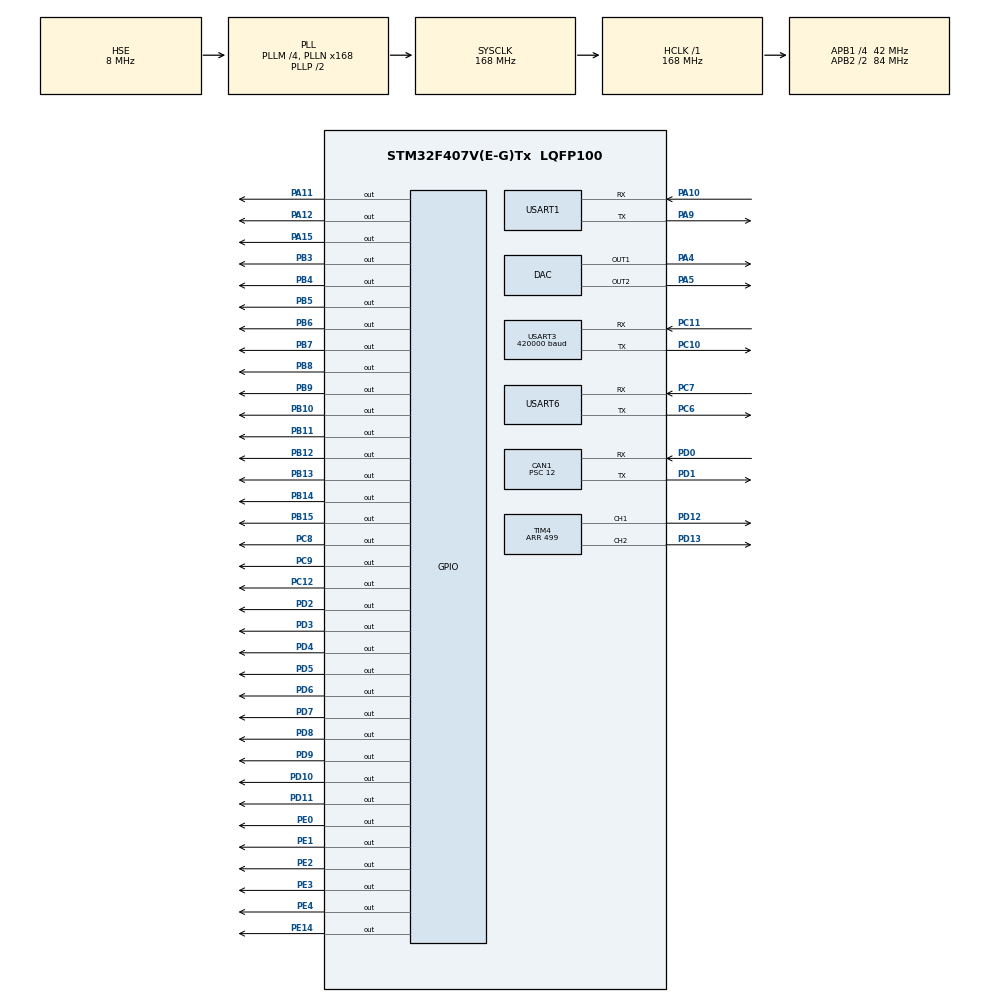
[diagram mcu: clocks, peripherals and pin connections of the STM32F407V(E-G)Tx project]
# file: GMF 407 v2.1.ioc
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CAN1.BS1=CAN_BS1_11TQ
CAN1.BS2=CAN_BS2_2TQ
CAN1.CalculateBaudRate=250000
CAN1.CalculateTimeBit=3999.99
CAN1.CalculateTimeQuantum=285.7142857142857
CAN1.Prescaler=12
Dma.Request0=USART3_RX
Dma.USART3_RX.0.Direction=DMA_PERIPH_TO_MEMORY
Dma.USART3_RX.0.FIFOMode=DMA_FIFOMODE_DISABLE
Dma.USART3_RX.0.Instance=DMA1_Stream1
Dma.USART3_RX.0.MemDataAlignment=DMA_MDATAALIGN_BYTE
Dma.USART3_RX.0.MemInc=DMA_MINC_ENABLE
Dma.USART3_RX.0.Mode=DMA_CIRCULAR
Dma.USART3_RX.0.PeriphDataAlignment=DMA_PDATAALIGN_BYTE
Dma.USART3_RX.0.PeriphInc=DMA_PINC_DISABLE
Dma.USART3_RX.0.Priority=DMA_PRIORITY_LOW
Mcu.Family=STM32F4
Mcu.Name=STM32F407V(E-G)Tx
Mcu.Package=LQFP100
NVIC.CAN1_RX0_IRQn=true\:0\:0\:false\:false\:true\:true\:true
NVIC.CAN1_RX1_IRQn=true\:0\:0\:false\:false\:true\:true\:true
NVIC.DMA1_Stream1_IRQn=true\:0\:0\:false\:false\:true\:false\:true
NVIC.PriorityGroup=NVIC_PRIORITYGROUP_4
NVIC.USART3_IRQn=true\:0\:0\:false\:false\:true\:true\:true
PA10.Mode=Asynchronous
PA10.Signal=USART1_RX
PA11.Signal=GPIO_Output
PA12.Signal=GPIO_Output
PA15.Signal=GPIO_Output
PA4.Signal=COMP_DAC1_group
PA5.Signal=COMP_DAC2_group
PA9.Mode=Asynchronous
PA9.Signal=USART1_TX
PB10.Signal=GPIO_Output
PB11.Signal=GPIO_Output
PB12.Signal=GPIO_Output
PB13.Signal=GPIO_Output
PB14.Signal=GPIO_Output
PB15.Signal=GPIO_Output
PB3.Signal=GPIO_Output
PB4.Signal=GPIO_Output
PB5.Signal=GPIO_Output
PB6.Signal=GPIO_Output
PB7.Signal=GPIO_Output
PB8.Signal=GPIO_Output
PB9.Signal=GPIO_Output
PC10.Mode=Asynchronous
PC10.Signal=USART3_TX
PC11.Mode=Asynchronous
PC11.Signal=USART3_RX
PC12.Signal=GPIO_Output
PC6.Mode=Asynchronous
PC6.Signal=USART6_TX
PC7.Mode=Asynchronous
PC7.Signal=USART6_RX
PC8.Signal=GPIO_Output
PC9.Signal=GPIO_Output
PD0.Mode=CAN_Activate
PD0.Signal=CAN1_RX
PD1.Mode=CAN_Activate
PD1.Signal=CAN1_TX
PD10.Signal=GPIO_Output
PD11.Signal=GPIO_Output
PD12.Signal=S_TIM4_CH1
PD13.Signal=S_TIM4_CH2
PD2.Signal=GPIO_Output
PD3.Signal=GPIO_Output
PD4.Signal=GPIO_Output
PD5.Signal=GPIO_Output
PD6.Signal=GPIO_Output
PD7.Signal=GPIO_Output
PD8.Signal=GPIO_Output
PD9.Signal=GPIO_Output
PE0.Signal=GPIO_Output
PE1.Signal=GPIO_Output
PE14.Signal=GPIO_Output
PE2.Signal=GPIO_Output
PE3.Signal=GPIO_Output
PE4.Signal=GPIO_Output
PH0-OSC_IN.Mode=HSE-External-Oscillator
PH0-OSC_IN.Signal=RCC_OSC_IN
PH1-OSC_OUT.Mode=HSE-External-Oscillator
PH1-OSC_OUT.Signal=RCC_OSC_OUT
ProjectManager.HeapSize=0x200
ProjectManager.StackSize=0x400
ProjectManager.TargetToolchain=STM32CubeIDE
RCC.48MHZClocksFreq_Value=84000000
RCC.AHBFreq_Value=168000000
RCC.APB1CLKDivider=RCC_HCLK_DIV4
RCC.APB1Freq_Value=42000000
RCC.APB1TimFreq_Value=84000000
RCC.APB2CLKDivider=RCC_HCLK_DIV2
RCC.APB2Freq_Value=84000000
RCC.APB2TimFreq_Value=168000000
RCC.CortexFreq_Value=168000000
RCC.HCLKFreq_Value=168000000
RCC.HSE_VALUE=8000000
RCC.HSI_VALUE=16000000
RCC.LSE_VALUE=32768
RCC.PLLM=4
RCC.PLLN=168
RCC.PLLSourceVirtual=RCC_PLLSOURCE_HSE
RCC.SYSCLKFreq_VALUE=168000000
RCC.SYSCLKSource=RCC_SYSCLKSOURCE_PLLCLK
RCC.VCOOutputFreq_Value=336000000
SH.COMP_DAC1_group.0=DAC_OUT1,DAC_OUT1
SH.COMP_DAC2_group.0=DAC_OUT2,DAC_OUT2
SH.S_TIM4_CH1.0=TIM4_CH1,PWM Generation1 CH1
SH.S_TIM4_CH2.0=TIM4_CH2,PWM Generation2 CH2
TIM4.Channel-PWM\ Generation1\ CH1=TIM_CHANNEL_1
TIM4.Channel-PWM\ Generation2\ CH2=TIM_CHANNEL_2
TIM4.Period=499
USART1.VirtualMode=VM_ASYNC
USART3.BaudRate=420000
USART3.VirtualMode=VM_ASYNC
USART6.VirtualMode=VM_ASYNC
VP_TIM4_VS_ClockSourceINT.Mode=Internal
board=custom

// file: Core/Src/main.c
/* USER CODE BEGIN Header */
/**
  ******************************************************************************
  * @file           : main.c
  * @brief          : Main program body
  ******************************************************************************
  * @attention
  *
  * <h2><center>&copy; Copyright (c) 2022 STMicroelectronics.
  * All rights reserved.</center></h2>
  *
  * This software component is licensed by ST under BSD 3-Clause license,
  * the "License"; You may not use this file except in compliance with the
  * License. You may obtain a copy of the License at:
  *                        opensource.org/licenses/BSD-3-Clause
  *
  ******************************************************************************
  */
/* USER CODE END Header */
#include "main.h"
#include "can.h"
#include "dac.h"
#include "dma.h"
#include "tim.h"
#include "usart.h"
#include "gpio.h"

/* USER CODE BEGIN Includes */
#include "radio.h"
#include "votol.h"
#include "can_stuff.h"
/* USER CODE END Includes */

void SystemClock_Config(void);

int main(void)
{

  /* MCU Configuration--------------------------------------------------------*/

  /* Reset of all peripherals, Initializes the Flash interface and the Systick. */
  HAL_Init();

  /* Configure the system clock */
  SystemClock_Config();

  /* Initialize all configured peripherals */
  MX_GPIO_Init();
  MX_TIM4_Init();
  MX_DMA_Init();
  MX_USART1_UART_Init();
  MX_USART3_UART_Init();
  MX_USART6_UART_Init();
  MX_DAC_Init();
  MX_CAN1_Init();
  /* USER CODE BEGIN 2 */
//  start_radio(&huart3);

  start_votol();

  HAL_UART_Receive_DMA(&huart3, &serial_byte, 1);
  /* USER CODE END 2 */

  /* Infinite loop */
  /* USER CODE BEGIN WHILE */
  while (1)
  {
	  kontrol_votol();
	  HAL_Delay(50);
    /* USER CODE END WHILE */

  }
}

void SystemClock_Config(void)
{
  RCC_OscInitTypeDef RCC_OscInitStruct = {0};
  RCC_ClkInitTypeDef RCC_ClkInitStruct = {0};

  /** Configure the main internal regulator output voltage
  */
  __HAL_RCC_PWR_CLK_ENABLE();
  __HAL_PWR_VOLTAGESCALING_CONFIG(PWR_REGULATOR_VOLTAGE_SCALE1);
  /** Initializes the RCC Oscillators according to the specified parameters
  * in the RCC_OscInitTypeDef structure.
  */
  RCC_OscInitStruct.OscillatorType = RCC_OSCILLATORTYPE_HSE;
  RCC_OscInitStruct.HSEState = RCC_HSE_ON;
  RCC_OscInitStruct.PLL.PLLState = RCC_PLL_ON;
  RCC_OscInitStruct.PLL.PLLSource = RCC_PLLSOURCE_HSE;
  RCC_OscInitStruct.PLL.PLLM = 4;
  RCC_OscInitStruct.PLL.PLLN = 168;
  RCC_OscInitStruct.PLL.PLLP = RCC_PLLP_DIV2;
  RCC_OscInitStruct.PLL.PLLQ = 4;
  if (HAL_RCC_OscConfig(&RCC_OscInitStruct) != HAL_OK)
  {
    Error_Handler();
  }
  /** Initializes the CPU, AHB and APB buses clocks
  */
  RCC_ClkInitStruct.ClockType = RCC_CLOCKTYPE_HCLK|RCC_CLOCKTYPE_SYSCLK
                              |RCC_CLOCKTYPE_PCLK1|RCC_CLOCKTYPE_PCLK2;
  RCC_ClkInitStruct.SYSCLKSource = RCC_SYSCLKSOURCE_PLLCLK;
  RCC_ClkInitStruct.AHBCLKDivider = RCC_SYSCLK_DIV1;
  RCC_ClkInitStruct.APB1CLKDivider = RCC_HCLK_DIV4;
  RCC_ClkInitStruct.APB2CLKDivider = RCC_HCLK_DIV2;

  if (HAL_RCC_ClockConfig(&RCC_ClkInitStruct, FLASH_LATENCY_5) != HAL_OK)
  {
    Error_Handler();
  }
}

/* USER CODE BEGIN 4 */
void HAL_UART_RxCpltCallback(UART_HandleTypeDef *huart){
	if(huart->Instance == USART3){
		parse_frame();
	}
}
/* USER CODE END 4 */

void Error_Handler(void)
{
  __disable_irq();
  while (1)
  {
  }
}

/************************ (C) COPYRIGHT STMicroelectronics *****END OF FILE****/
